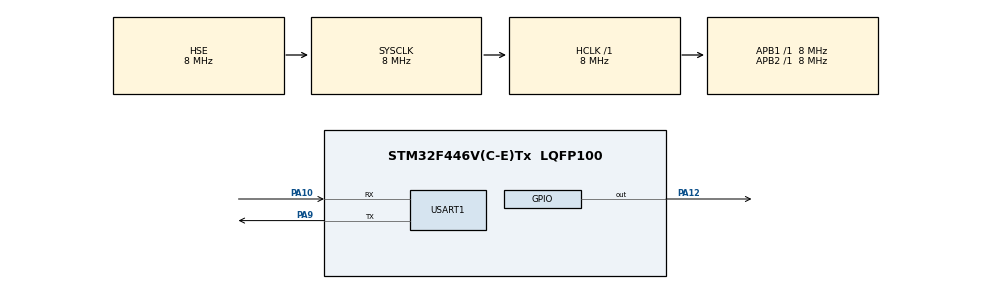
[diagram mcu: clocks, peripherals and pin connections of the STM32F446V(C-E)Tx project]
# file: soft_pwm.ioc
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Mcu.Family=STM32F4
Mcu.Name=STM32F446V(C-E)Tx
Mcu.Package=LQFP100
NVIC.PriorityGroup=NVIC_PRIORITYGROUP_4
NVIC.TIM8_UP_TIM13_IRQn=true\:0\:0\:false\:false\:true
PA10.Mode=Asynchronous
PA10.Signal=USART1_RX
PA12.Signal=GPIO_Output
PA9.Mode=Asynchronous
PA9.Signal=USART1_TX
PH0-OSC_IN.Mode=HSE-External-Oscillator
PH0-OSC_IN.Signal=RCC_OSC_IN
PH1-OSC_OUT.Mode=HSE-External-Oscillator
PH1-OSC_OUT.Signal=RCC_OSC_OUT
ProjectManager.HeapSize=0x200
ProjectManager.StackSize=0x400
ProjectManager.TargetToolchain=TrueSTUDIO
RCC.AHBFreq_Value=8000000
RCC.APB1Freq_Value=8000000
RCC.APB1TimFreq_Value=8000000
RCC.APB2Freq_Value=8000000
RCC.APB2TimFreq_Value=8000000
RCC.CortexFreq_Value=8000000
RCC.HCLKFreq_Value=8000000
RCC.HSE_VALUE=8000000
RCC.PLLSourceVirtual=RCC_PLLSOURCE_HSE
RCC.SYSCLKFreq_VALUE=8000000
RCC.SYSCLKSource=RCC_SYSCLKSOURCE_HSE
RCC.USBFreq_Value=48000000
RCC.VCOOutputFreq_Value=96000000
TIM13.Period=10
TIM13.Prescaler=1000
VP_TIM13_VS_ClockSourceINT.Mode=Enable_Timer
board=soft_pwm

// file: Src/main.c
/**
  ******************************************************************************
  * File Name          : main.c
  * Description        : Main program body
  ******************************************************************************
  *
  * COPYRIGHT(c) 2016 STMicroelectronics
  *
  * Redistribution and use in source and binary forms, with or without modification,
  * are permitted provided that the following conditions are met:
  *   1. Redistributions of source code must retain the above copyright notice,
  *      this list of conditions and the following disclaimer.
  *   2. Redistributions in binary form must reproduce the above copyright notice,
  *      this list of conditions and the following disclaimer in the documentation
  *      and/or other materials provided with the distribution.
  *   3. Neither the name of STMicroelectronics nor the names of its contributors
  *      may be used to endorse or promote products derived from this software
  *      without specific prior written permission.
  *
  * THIS SOFTWARE IS PROVIDED BY THE COPYRIGHT HOLDERS AND CONTRIBUTORS "AS IS"
  * AND ANY EXPRESS OR IMPLIED WARRANTIES, INCLUDING, BUT NOT LIMITED TO, THE
  * IMPLIED WARRANTIES OF MERCHANTABILITY AND FITNESS FOR A PARTICULAR PURPOSE ARE
  * DISCLAIMED. IN NO EVENT SHALL THE COPYRIGHT HOLDER OR CONTRIBUTORS BE LIABLE
  * FOR ANY DIRECT, INDIRECT, INCIDENTAL, SPECIAL, EXEMPLARY, OR CONSEQUENTIAL
  * DAMAGES (INCLUDING, BUT NOT LIMITED TO, PROCUREMENT OF SUBSTITUTE GOODS OR
  * SERVICES; LOSS OF USE, DATA, OR PROFITS; OR BUSINESS INTERRUPTION) HOWEVER
  * CAUSED AND ON ANY THEORY OF LIABILITY, WHETHER IN CONTRACT, STRICT LIABILITY,
  * OR TORT (INCLUDING NEGLIGENCE OR OTHERWISE) ARISING IN ANY WAY OUT OF THE USE
  * OF THIS SOFTWARE, EVEN IF ADVISED OF THE POSSIBILITY OF SUCH DAMAGE.
  *
  ******************************************************************************
  */
#include "stm32f4xx_hal.h"
#include "tim.h"
#include "usart.h"
#include "gpio.h"

/* USER CODE BEGIN PV */
/* Private variables ---------------------------------------------------------*/

/* USER CODE END PV */

void SystemClock_Config(void);
void Error_Handler(void);

/* USER CODE BEGIN PFP */
/* Private function prototypes -----------------------------------------------*/

/* USER CODE END PFP */

int main(void)
{

  /* MCU Configuration----------------------------------------------------------*/

  /* Reset of all peripherals, Initializes the Flash interface and the Systick. */
  HAL_Init();

  /* Configure the system clock */
  SystemClock_Config();

  /* Initialize all configured peripherals */
  MX_GPIO_Init();
  MX_TIM13_Init();
  MX_USART1_UART_Init();

  /* USER CODE BEGIN 2 */
  HAL_TIM_Base_Start_IT(&htim13);
  /* USER CODE END 2 */

  /* Infinite loop */
  while (1)
  {

  }

}

/** System Clock Configuration
*/
void SystemClock_Config(void)
{

  RCC_OscInitTypeDef RCC_OscInitStruct;
  RCC_ClkInitTypeDef RCC_ClkInitStruct;

  __HAL_RCC_PWR_CLK_ENABLE();

  __HAL_PWR_VOLTAGESCALING_CONFIG(PWR_REGULATOR_VOLTAGE_SCALE3);

  RCC_OscInitStruct.OscillatorType = RCC_OSCILLATORTYPE_HSE;
  RCC_OscInitStruct.HSEState = RCC_HSE_ON;
  RCC_OscInitStruct.PLL.PLLState = RCC_PLL_NONE;
  if (HAL_RCC_OscConfig(&RCC_OscInitStruct) != HAL_OK)
  {
    Error_Handler();
  }

  RCC_ClkInitStruct.ClockType = RCC_CLOCKTYPE_HCLK|RCC_CLOCKTYPE_SYSCLK
                              |RCC_CLOCKTYPE_PCLK1|RCC_CLOCKTYPE_PCLK2;
  RCC_ClkInitStruct.SYSCLKSource = RCC_SYSCLKSOURCE_HSE;
  RCC_ClkInitStruct.AHBCLKDivider = RCC_SYSCLK_DIV1;
  RCC_ClkInitStruct.APB1CLKDivider = RCC_HCLK_DIV1;
  RCC_ClkInitStruct.APB2CLKDivider = RCC_HCLK_DIV1;
  if (HAL_RCC_ClockConfig(&RCC_ClkInitStruct, FLASH_LATENCY_0) != HAL_OK)
  {
    Error_Handler();
  }

  HAL_SYSTICK_Config(HAL_RCC_GetHCLKFreq()/1000);

  HAL_SYSTICK_CLKSourceConfig(SYSTICK_CLKSOURCE_HCLK);

  /* SysTick_IRQn interrupt configuration */
  HAL_NVIC_SetPriority(SysTick_IRQn, 0, 0);
}

/* USER CODE BEGIN 4 */
void HAL_TIM_PeriodElapsedCallback(TIM_HandleTypeDef *htim){
		if(htim == &htim13){
			HAL_GPIO_TogglePin(GPIOA, GPIO_PIN_12);
		}
}
/* USER CODE END 4 */

void Error_Handler(void)
{
  while(1)
  {
  }
}

/************************ (C) COPYRIGHT STMicroelectronics *****END OF FILE****/
